# PIC32CM5164JH00032 device description
Architecture: CORTEX-M0PLUS; Family: PIC32CM; Series: PIC32CMJH00
Registers are 32-bit, read-write, reset 0x0 unless marked. A register's access mark holds for its fields unless they carry their own. Offsets are from the block's base; [hi:lo] are bit positions; {n}, {i} and the like mark numbered series.

## MPU — Memory Protection Unit
Instances: MPU 0xE000ED90
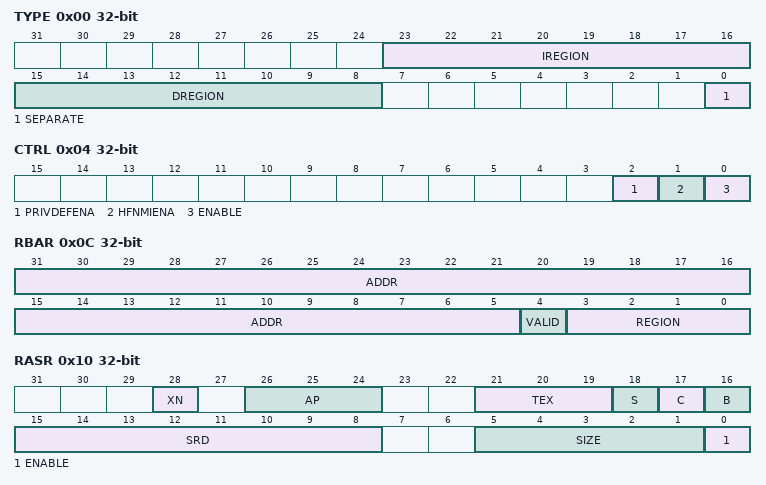
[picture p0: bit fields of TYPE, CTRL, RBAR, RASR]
0x00 TYPE ro reset not defined — MPU Type Register
  [23:16] IREGION — Number of Instruction Regions
  [15:8] DREGION — Number of Data Regions
  [0] SEPARATE — Separate instruction and Data Memory MapsRegions
0x04 CTRL reset not defined — MPU Control Register
  [2] PRIVDEFENA — Enables privileged software access to default memory map
  [1] HFNMIENA — Enable Hard Fault and NMI handlers
  [0] ENABLE — MPU Enable
0x08 RNR reset not defined — MPU Region Number Register
  [7:0] REGION — Region referenced by RBAR and RASR
0x0C RBAR reset not defined — MPU Region Base Address Register
  [31:5] ADDR — Region base address
  [4] VALID — Region number valid
  [3:0] REGION — Region number
0x10 RASR reset not defined — MPU Region Attribute and Size Register
  [28] XN — Execute Never Attribute
  [26:24] AP — Access Permission
  [21:19] TEX — TEX bit
  [18] S — Shareable bit
  [17] C — Cacheable bit
  [16] B — Bufferable bit
  [15:8] SRD — Sub-region disable
  [5:1] SIZE — Region Size
  [0] ENABLE — Region Enable

## MTB — Cortex-M0+ Micro-Trace Buffer
Instances: MTB 0x41008000
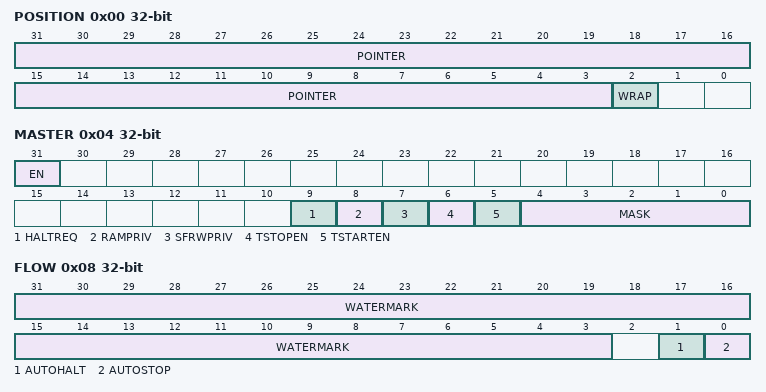
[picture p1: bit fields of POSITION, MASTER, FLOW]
0x00 POSITION reset not defined — MTB Position
  [31:3] POINTER — Trace Packet Location Pointer
  [2] WRAP — Pointer Value Wraps
0x04 MASTER — MTB Master
  [31] EN — Main Trace Enable
  [9] HALTREQ — Halt Request
  [8] RAMPRIV — SRAM Privilege
  [7] SFRWPRIV — Special Function Register Write Privilege
  [6] TSTOPEN — Trace Stop Input Enable
  [5] TSTARTEN — Trace Start Input Enable
  [4:0] MASK — Maximum Value of the Trace Buffer in SRAM
0x08 FLOW — MTB Flow
  [31:3] WATERMARK — Watermark value
  [1] AUTOHALT — Auto Halt Request
  [0] AUTOSTOP — Auto Stop Tracing
0x0C BASE ro reset not defined — MTB Base
0xF00 ITCTRL reset not defined — MTB Integration Mode Control
0xFA0 CLAIMSET reset not defined (atomic set) — MTB Claim Set
0xFA4 CLAIMCLR reset not defined (atomic clear) — MTB Claim Clear
0xFB0 LOCKACCESS reset not defined — MTB Lock Access
0xFB4 LOCKSTATUS ro reset not defined — MTB Lock Status
0xFB8 AUTHSTATUS ro reset not defined — MTB Authentication Status
0xFBC DEVARCH ro reset not defined — MTB Device Architecture
0xFC8 DEVID ro reset not defined — MTB Device Configuration
0xFCC DEVTYPE ro reset not defined — MTB Device Type
{0xFC0+4i} PID{i} ro reset not defined (i=4..7) — Peripheral Identification {i}
{0xFE0+4i} PID{i} ro reset not defined (i=0..3) — Peripheral Identification {i}
{0xFF0+4i} CID{i} ro reset not defined (i=0..3) — Component Identification {i}

## NVIC — Nested Vectored Interrupt Controller
Instances: NVIC 0xE000E100
0x00 ISER — Interrupt Set Enable Register
  [31:0] SETENA — Interrupt set enable bits
0x80 ICER — Interrupt Clear Enable Register
  [31:0] CLRENA — Interrupt clear-enable bits
0x100 ISPR — Interrupt Set Pending Register
  [31:0] SETPEND — Interrupt set-pending bits
0x180 ICPR — Interrupt Clear Pending Register
  [31:0] CLRPEND — Interrupt clear-pending bits
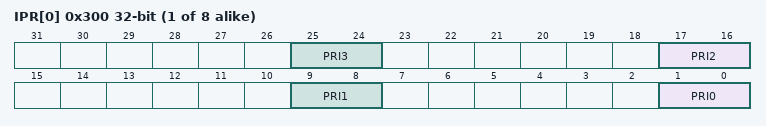
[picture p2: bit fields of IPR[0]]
{0x300+4i} IPR[{i}] (i=0..7) — Interrupt Priority Register n
  [8n+1:8n] PRI{n} (n=0..3) — Priority of interrupt n

## LOCKBIT_FUSES — Non-Volatile Fuses
Instances: LOCKBIT_FUSES 0x00802000 in fuses
0x00 LOCKBIT_WORD_0 ro reset not defined — LOCKBIT Page Word 0
  [29:24] NVMCTRL_CEHL — CEHL Bits

## OTP1_FUSES — Non-Volatile Fuses
Instances: OTP1_FUSES 0x00806000 in fuses
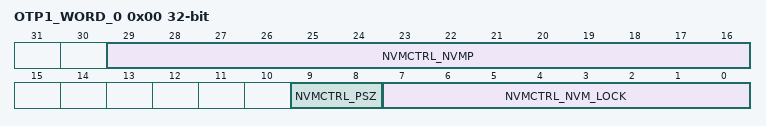
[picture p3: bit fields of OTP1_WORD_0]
0x00 OTP1_WORD_0 ro reset not defined — OTP1 Page Word 0
  [29:16] NVMCTRL_NVMP — Number of NVM Pages
  [9:8] NVMCTRL_PSZ — NVM Page Size
  [7:0] NVMCTRL_NVM_LOCK — NVM Lock
0x04 OTP1_WORD_1 ro reset not defined — OTP1 Page Word 1
  [7:0] NVMCTRL_DATAFLASHP — Number of Data Flash Pages

## Notices in the file
Copyright (c) 2019 Microchip Technology Inc.
SPDX-License-Identifier: Apache-2.0
Licensed under the Apache License, Version 2.0 (the "License");
you may not use this file except in compliance with the License.
You may obtain a copy of the License at
http://www.apache.org/licenses/LICENSE-2.0
Unless required by applicable law or agreed to in writing, software
distributed under the License is distributed on an "AS IS" BASIS,
WITHOUT WARRANTIES OR CONDITIONS OF ANY KIND, either express or implied.
See the License for the specific language governing permissions and
limitations under the License.
